# NUC505_v1 register map
File version: 1.0
Registers are 32-bit, read-write, reset 0x0 unless marked. A register's access mark holds for its fields unless they carry their own. Offsets are from the block's base; [hi:lo] are bit positions; lines under a group give offsets from that group; {n}, {i} and the like mark numbered series; 'fields as' and 'values as' point back to an identical list.

## GCR — GCR Register Map
Base 0x40000000
0x00 SYS_PDID ro reset 0x550505 — Part Device Identification Number Register
  [23:0] PDID — Part Device Identification Number (Read Only). This register reflects device part number code. Software can read this register to identify which device is used.
0x04 SYS_BOOTSET (reset mask 0xFFFFFF00) — System Power-on Configuration Register
  [3:0] BOOTSET — System Mode Configuration. Note: If BOOTSET is equal to ICE Mode, the software cannot change BOOTSET to other mode. But other modes don't have this limitation.
    6=Boot from ICE Mode with external SPI Flash; 7=Boot from ICE Mode with SPI Flash; 11=Boot from ICP Mode; 13=Boot from external SPI Flash; 14=Boot from USB; 15=Boot from SPI Flash
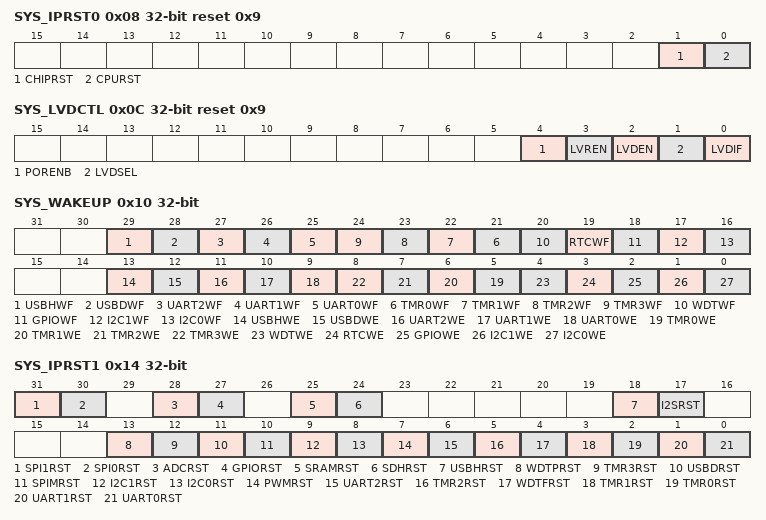
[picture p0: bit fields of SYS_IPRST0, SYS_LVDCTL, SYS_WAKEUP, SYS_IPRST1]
0x08 SYS_IPRST0 reset 0x9 — Peripheral Reset Control Register 0
  [1] CHIPRST — Chip One-shot Reset. Setting this bit will reset the whole chip, including processor core and all peripherals, and this bit will automatically return to 0 after the 2 clock cycles. The CHIPRST is same as the POR reset, all the chip controllers is reset and the chip setting from flash are also reload.
    0=Chip normal operation; 1=Chip one-shot reset
  [0] CPURST — Processor Core One-shot Reset. Setting this bit will only reset the processor core, and this bit will automatically return to 0 after the 2 clock cycles.
    0=Processor core normal operation; 1=Processor core one-shot reset
0x0C SYS_LVDCTL reset 0x9 — Low Voltage Detection Control Register
  [4] PORENB — Power on Reset Enable Control
    0=Function Enabled. (Default); 1=Function Disabled
  [3] LVREN — Low Voltage Reset Enable Control. Note: The voltage threshold level is 2.4V
    0=Low Voltage Reset Disabled; 1=Low Voltage Reset Enabled. (default)
  [2] LVDEN — Low Voltage Detection Enable Control
    0=Detection Disabled; 1=Detection Enabled
  [1] LVDSEL — Low Voltage Detection Level Selection
    0=The threshold level is 2.6V; 1=The threshold level is 2.8V
  [0] LVDIF — Low Voltage Detect Flag. Note: This bit is useful when LVDEN is enabled.
    0=Low voltage Period; 1=Normal voltage Period
0x10 SYS_WAKEUP — Wake-up Control and Status Resister
  [29] USBHWF — USB Host Wake-up Flag. Note: Write 1 to clear this bit
    0=USB Host wake-up source is deasserted; 1=USB Host wake-up source is asserted
  [28] USBDWF — USB Device Wake-up Flag. Note: Write 1 to clear this bit
    0=USB Device wake-up source is deasserted; 1=USB Device wake-up source is asserted
  [27] UART2WF — UART2 Wake-up Flag. Note: Write 1 to clear this bit
    0=UART2 wake-up source is deasserted; 1=UART2 wake-up source is asserted
  [26] UART1WF — UART1 Wake-up Flag. Note: Write 1 to clear this bit
    0=UART1 wake-up source is deasserted; 1=UART1 wake-up source is asserted
  [25] UART0WF — UART0 Wake-up Flag. Note: Write 1 to clear this bit
    0=UART0 wake-up source is deasserted; 1=UART0 wake-up source is asserted
  [n+21] TMR{n}WF (n=0..3) — Timer{n} Wake-up Flag. Note: Write 1 to clear this bit
    0=Timer{n} wake-up source is deasserted; 1=Timer{n} wake-up source is asserted
  [20] WDTWF — WDT Wake-up Flag. Note: Write 1 to clear this bit
    0=WDT wake-up source is deasserted; 1=WDT wake-up source is asserted
  [19] RTCWF — RTC Wake-up Flag. Note: Write 1 to clear this bit
    0=RTC wake-up source is deasserted; 1=RTC wake-up source is asserted
  [18] GPIOWF — GPIO Wake-up Flag. Note: Write 1 to clear this bit
    0=GPIO wake-up source is deasserted; 1=GPIO wake-up source is asserted
  [17] I2C1WF — I2C1 Wake-up Flag. Note: Write 1 to clear this bit
    0=I2C1 wake-up source is deasserted; 1=I2C1 wake-up source is asserted
  [16] I2C0WF — I2C0 Wake-up Flag. Note: Write 1 to clear this bit
    0=I2C0 wake-up source is deasserted; 1=I2C0 wake-up source is asserted
  [13] USBHWE — USB Host Wake-up Enable Control
    0=USB Host wake-up Disabled; 1=USB Host wake-up Enabled
  [12] USBDWE — USB Device Wake-up Enable Control
    0=USB Device wake-up Disabled; 1=USB Device wake-up Enabled
  [11] UART2WE — UART2 Wake-up Enable Control
    0=UART2 wake-up Disabled; 1=UART2 wake-up Enabled
  [10] UART1WE — UART1 Wake-up Enable Control
    0=UART1 wake-up Disabled; 1=UART1 wake-up Enabled
  [9] UART0WE — UART0 Wake-up Enable Control
    0=UART0 wake-up Disabled; 1=UART0 wake-up Enabled
  [n+5] TMR{n}WE (n=0..3) — Timer{n} Wake-up Enable Control
    0=Timer{n} wake-up Disabled; 1=Timer{n} wake-up Enabled
  [4] WDTWE — WDT Wake-up Enable Control
    0=WDT wake-up Disabled; 1=WDT wake-up Enabled
  [3] RTCWE — RTC Wake-up Enable Control
    0=RTC wake-up Disabled; 1=RTC wake-up Enabled
  [2] GPIOWE — GPIO Wake-up Enable Control
    0=GPIO wake-up Disabled; 1=GPIO wake-up Enabled
  [1] I2C1WE — I2C1 Wake-up Enable Control
    0=I2C1 wake-up Disabled; 1=I2C1 wake-up Enabled
  [0] I2C0WE — I2C0 Wake-up Enable Control
    0=I2C0 wake-up Disabled; 1=I2C0 wake-up Enabled
0x14 SYS_IPRST1 — Peripheral Reset Control Register 1
  [31] SPI1RST — SPI1 Controller Reset. Set this bit to 1 will generate a reset signal to the USB host controller. User needs to set this bit to 0 to release from the reset state.
    0=SPI1 controller normal operation; 1=SPI1 controller reset
  [30] SPI0RST — SPI0 Controller Reset. Set this bit to 1 will generate a reset signal to the USB host controller. User needs to set this bit to 0 to release from the reset state.
    0=SPI0 controller normal operation; 1=SPI0 controller reset
  [28] ADCRST — ADC Controller Reset. Set this bit to 1 will generate a reset signal to the USB host controller. User needs to set this bit to 0 to release from the reset state.
    0=ADC controller normal operation; 1=ADC controller reset
  [27] GPIORST — GPIO Controller Reset. Set this bit to 1 will generate a reset signal to the USB host controller. User needs to set this bit to 0 to release from the reset state.
    0=GPIO controller normal operation; 1=GPIO controller reset
  [25] SRAMRST — SRAM Controller Reset. Set this bit to 1 will generate a reset signal to the USB host controller. User needs to set this bit to 0 to release from the reset state.
    0=SRAM controller normal operation; 1=SRAM controller reset
  [24] SDHRST — SDH Controller Reset. Set this bit to 1 will generate a reset signal to the USB host controller. User needs to set this bit to 0 to release from the reset state.
    0=SDH controller normal operation; 1=SDH controller reset
  [18] USBHRST — USB Host Controller Reset. Setting this bit to 1 will generate a reset signal to the USB host controller. User needs to set this bit to 0 to release from the reset state.
    0=USB Host controller normal operation; 1=USB Host controller reset
  [17] I2SRST — I2S Controller Reset. Setting this bit to 1 will generate a reset signal to the USB host controller. User needs to set this bit to 0 to release from the reset state.
    0=I2S controller normal operation; 1=I2S controller reset
  [13] WDTPRST — WDT Controller Reset. Setting this bit to 1 will generate a reset signal to the USB host controller. User needs to set this bit to 0 to release from the reset state.
    0=WDT controller normal operation; 1=WDT controller reset
  [12] TMR3RST — Timer3 Controller Reset. Setting this bit to 1 will generate a reset signal to the USB host controller. User needs to set this bit to 0 to release from the reset state.
    0=Timer3 controller normal operation; 1=Timer3 controller reset
  [11] USBDRST — USB Device Controller Reset. Setting this bit to 1 will generate a reset signal to the USB host controller. User needs to set this bit to 0 to release from the reset state.
    0=USB Device controller normal operation; 1=USB Device controller reset
  [10] SPIMRST — SPIM Controller Reset. Setting this bit to 1 will generate a reset signal to the USB host controller. User needs to set this bit to 0 to release from the reset state.
    0=SPIM controller normal operation; 1=SPIM controller reset
  [9] I2C1RST — I2C1 Controller Reset. Setting this bit to 1 will generate a reset signal to the USB host controller. User needs to set this bit to 0 to release from the reset state.
    0=I2C1 controller normal operation; 1=I2C1 controller reset
  [8] I2C0RST — I2C0 Controller Reset. Setting this bit to 1 will generate a reset signal to the USB host controller. User needs to set this bit to 0 to release from the reset state.
    0=I2C0 controller normal operation; 1=I2C0 controller reset
  [7] PWMRST — PWM Controller Reset. Setting this bit to 1 will generate a reset signal to the USB host controller. User needs to set this bit to 0 to release from the reset state.
    0=PWM controller normal operation; 1=PWM controller reset
  [6] UART2RST — UART2 Controller Reset. Setting this bit to 1 will generate a reset signal to the USB host controller. User needs to set this bit to 0 to release from the reset state.
    0=UART2 controller normal operation; 1=UART2 controller reset
  [5] TMR2RST — Timer2 Controller Reset. Setting this bit to 1 will generate a reset signal to the USB host controller. User needs to set this bit to 0 to release from the reset state.
    0=Timer2 controller normal operation; 1=Timer2 controller reset
  [4] WDTFRST — WDT Hardware Controller Reset. Setting this bit to 1 will generate a reset signal to the USB host controller. User needs to set this bit to 0 to release from the reset state.
    0=WDT controller normal operation; 1=WDT controller reset
  [3] TMR1RST — Timer1 Controller Reset. Setting this bit to 1 will generate a reset signal to the USB host controller. User needs to set this bit to 0 to release from the reset state.
    0=Timer1 controller normal operation; 1=Timer1 controller reset
  [2] TMR0RST — Timer0 Controller Reset. Setting this bit to 1 will generate a reset signal to the USB host controller. User needs to set this bit to 0 to release from the reset state.
    0=Timer0 controller normal operation; 1=Timer0 controller reset
  [1] UART1RST — UART1 Controller Reset. Setting this bit to 1 will generate a reset signal to the USB host controller. User needs to set this bit to 0 to release from the reset state.
    0=UART1 controller normal operation; 1=UART1 controller reset
  [0] UART0RST — UART0 Controller Reset. Setting this bit to 1 will generate a reset signal to the USB host controller. User needs to set this bit to 0 to release from the reset state.
    0=UART0 controller normal operation; 1=UART0 controller reset
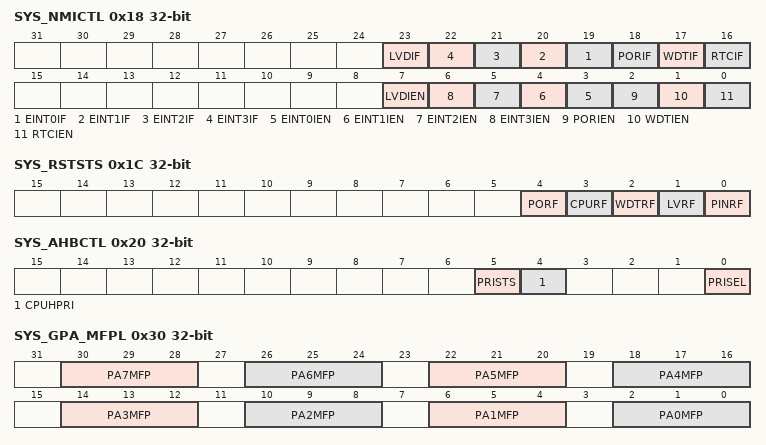
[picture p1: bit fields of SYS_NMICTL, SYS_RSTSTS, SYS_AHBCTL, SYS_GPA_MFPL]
0x18 SYS_NMICTL — Non Maskable Interrupt Control Register
  [23] LVDIF ro — Low Voltage Detect (LVD) Interrupt Flag (Read Only)
    0=LVD interrupt is deasserted; 1=LVD interrupt is asserted
  [n+19] EINT{n}IF ro (n=0..3) — External GPIO Group {n} Interrupt Flag (Read Only)
    0=External GPIO group {n} interrupt is deasserted; 1=External GPIO group {n} interrupt is asserted
  [18] PORIF ro — Power on Reset (POR) Interrupt Flag (Read Only)
    0=POR interrupt is deasserted; 1=POR interrupt is asserted
  [17] WDTIF ro — Watch Dog Timer (WDT) Interrupt Flag (Read Only)
    0=WDT interrupt is deasserted; 1=WDT interrupt is asserted
  [16] RTCIF ro — RTC Interrupt Flag (Read Only)
    0=RTC interrupt is deasserted; 1=RTC interrupt is asserted
  [7] LVDIEN — Low Voltage Detect NMI Source Enable Control
    0=LVD NMI source Disabled; 1=LVD NMI source Enabled
  [n+3] EINT{n}IEN (n=0..3) — External GPIO Group {n} NMI Source Enable Control
    0=External GPIO group {n} NMI source Disabled; 1=External GPIO group {n} NMI source Enabled
  [2] PORIEN — Power on Interrupt NMI Source Enable Control
    0=POR NMI source Disabled; 1=POR NMI source Enabled
  [1] WDTIEN — WDT Interrupt NMI Source Enable Control
    0=WDT NMI source Disabled; 1=WDT NMI source Enabled
  [0] RTCIEN — RTC Interrupt NMI Source Enable Control
    0=RTC NMI source Disabled; 1=RTC NMI source Enabled
0x1C SYS_RSTSTS — Reset Status Control Register
  [4] PORF — Reset Status for POR Reset. Note: Write 1 to clear this bit to 0.
    0=No effect; 1=Power-on Reset (POR) had issued the reset signal to reset the system
  [3] CPURF — Reset Status for Software Setting. Note: Write 1 to clear this bit to 0.
    0=No effect; 1=The CPURST had be triggered to reset the CPU or the CHIPREST had be triggered to reset the system
  [2] WDTRF — Reset Status for Watch Dog Reset. Note: Write 1 to clear this bit to 0.
    0=No effect; 1=The watchdog timer or window watchdog timer had issued the reset signal to reset the system
  [1] LVRF — Reset Status for Low Voltage Reset. Note: Write 1 to clear this bit to 0.
    0=No effect; 1=LVR controller had issued the reset signal to reset the system
  [0] PINRF — Reset Status for External NReset Pin. Note: Write 1 to clear this bit to 0.
    0=No effect; 1=nRESET pin had issued the reset signal to reset the system
0x20 SYS_AHBCTL — AHB Bus Control Register
  [5] PRISTS — Interrupt Active Status in CPUHPRI Enabled Mode. If it is high, the CPU has the highest AHB bus priority. It is set when the CPUHPRI is enabled and the external IRQ is active. This bit is cleared by writing 1 to it. Therefore, if exiting from the IRQ when CPUHPRI is enabled, PRISTS must be cleared. Otherwise, the CPU always has the highest AHB bus priority.
    0=No effect; 1=The highest AHB bus priority for CPU is active
  [4] CPUHPRI — Enable Raising the Priority of CPU in IRQ Period. It can be used to reduce the interrupt latency in a real-time system. Setting this bit, the CPU will have the highest AHB priority.
    0=No effect; 1=The function that CPU has the highest AHB bus priority in IRQ period Enabled
  [0] PRISEL — AHB Bus Arbitration Mode Control. The priority mode for fixed priority mode is I2S SDH USBH USBD SPIM M4(S) M4(D) M4(I)
    0=Fixed priority mode; 1=Round-robin priority mode (rotate)
0x30 SYS_GPA_MFPL — GPIOA Low Byte Multi-function Control Register
  [30:28] PA7MFP — PA.7 Multi-function Pin Selection
  [26:24] PA6MFP — PA.6 Multi-function Pin Selection
  [22:20] PA5MFP — PA.5 Multi-function Pin Selection
  [18:16] PA4MFP — PA.4 Multi-function Pin Selection
  [14:12] PA3MFP — PA.3 Multi-function Pin Selection
  [10:8] PA2MFP — PA.2 Multi-function Pin Selection
  [6:4] PA1MFP — PA.1 Multi-function Pin Selection
  [2:0] PA0MFP — PA.0 Multi-function Pin Selection
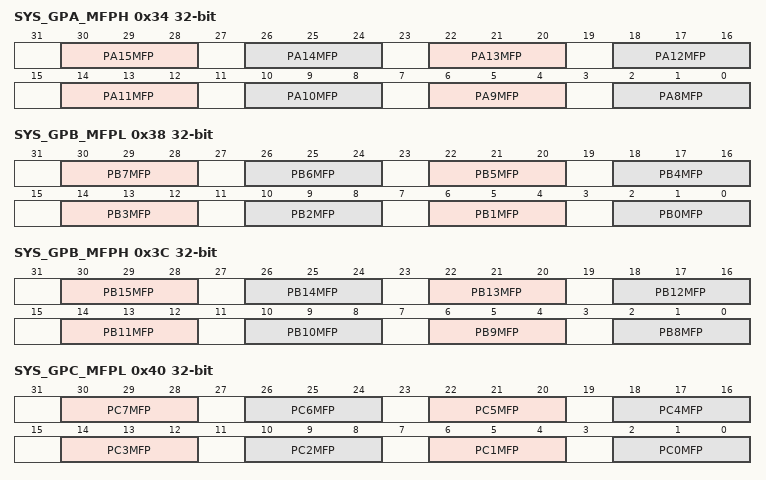
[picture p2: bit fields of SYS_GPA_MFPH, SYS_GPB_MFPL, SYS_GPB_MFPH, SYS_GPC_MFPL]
0x34 SYS_GPA_MFPH — GPIOA High Byte Multi-function Control Register
  [30:28] PA15MFP — PA.15 Multi-function Pin Selection
  [26:24] PA14MFP — PA.14 Multi-function Pin Selection
  [22:20] PA13MFP — PA.13 Multi-function Pin Selection
  [18:16] PA12MFP — PA.12 Multi-function Pin Selection
  [14:12] PA11MFP — PA.11 Multi-function Pin Selection
  [10:8] PA10MFP — PA.10 Multi-function Pin Selection
  [6:4] PA9MFP — PA.9 Multi-function Pin Selection
  [2:0] PA8MFP — PA.8 Multi-function Pin Selection
0x38 SYS_GPB_MFPL — GPIOB Low Byte Multi-function Control Register
  [30:28] PB7MFP — PB.7 Multi-function Pin Selection
  [26:24] PB6MFP — PB.6 Multi-function Pin Selection
  [22:20] PB5MFP — PB.5 Multi-function Pin Selection
  [18:16] PB4MFP — PB.4 Multi-function Pin Selection
  [14:12] PB3MFP — PB.3 Multi-function Pin Selection
  [10:8] PB2MFP — PB.2 Multi-function Pin Selection
  [6:4] PB1MFP — PB.1 Multi-function Pin Selection
  [2:0] PB0MFP — PB.0 Multi-function Pin Selection
0x3C SYS_GPB_MFPH — GPIOB High Byte Multi-function Control Register
  [30:28] PB15MFP — PB.15 Multi-function Pin Selection
  [26:24] PB14MFP — PB.14 Multi-function Pin Selection
  [22:20] PB13MFP — PB.13 Multi-function Pin Selection
  [18:16] PB12MFP — PB.12 Multi-function Pin Selection
  [14:12] PB11MFP — PB.11 Multi-function Pin Selection
  [10:8] PB10MFP — PB.10 Multi-function Pin Selection
  [6:4] PB9MFP — PB.9 Multi-function Pin Selection
  [2:0] PB8MFP — PB.8 Multi-function Pin Selection
0x40 SYS_GPC_MFPL — GPIOC Low Byte Multi-function Control Register
  [30:28] PC7MFP — PC.7 Multi-function Pin Selection
  [26:24] PC6MFP — PC.6 Multi-function Pin Selection
  [22:20] PC5MFP — PC.5 Multi-function Pin Selection
  [18:16] PC4MFP — PC.4 Multi-function Pin Selection
  [14:12] PC3MFP — PC.3 Multi-function Pin Selection
  [10:8] PC2MFP — PC.2 Multi-function Pin Selection
  [6:4] PC1MFP — PC.1 Multi-function Pin Selection
  [2:0] PC0MFP — PC.0 Multi-function Pin Selection
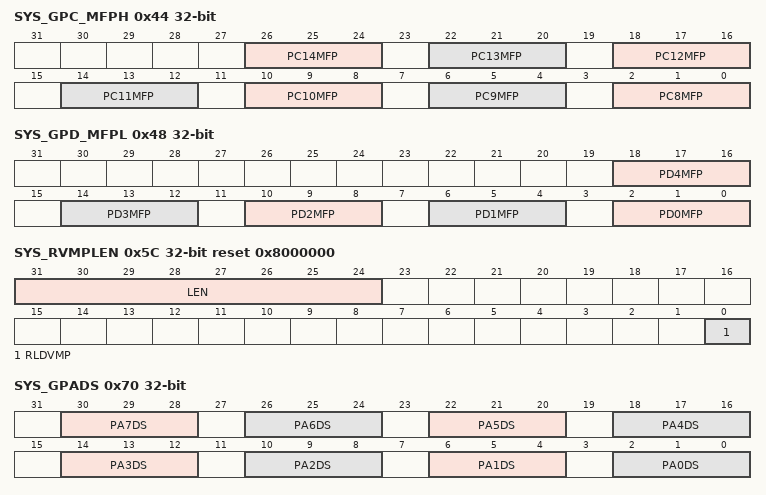
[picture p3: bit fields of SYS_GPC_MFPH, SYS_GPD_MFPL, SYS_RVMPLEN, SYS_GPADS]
0x44 SYS_GPC_MFPH — GPIOC High Byte Multi-function Control Register
  [26:24] PC14MFP — PC.14 Multi-function Pin Selection
  [22:20] PC13MFP — PC.13 Multi-function Pin Selection
  [18:16] PC12MFP — PC.12 Multi-function Pin Selection
  [14:12] PC11MFP — PC.11 Multi-function Pin Selection
  [10:8] PC10MFP — PC.10 Multi-function Pin Selection
  [6:4] PC9MFP — PC.9 Multi-function Pin Selection
  [2:0] PC8MFP — PC.8 Multi-function Pin Selection
0x48 SYS_GPD_MFPL — GPIOD Low Byte Multi-function Control Register
  [18:16] PD4MFP — PD.4 Multi-function Pin Selection
  [14:12] PD3MFP — PD.3 Multi-function Pin Selection
  [10:8] PD2MFP — PD.2 Multi-function Pin Selection
  [6:4] PD1MFP — PD.1 Multi-function Pin Selection
  [2:0] PD0MFP — PD.0 Multi-function Pin Selection
0x50 SYS_LVMPADDR reset 0x1FFF0000 — Load VECMAP Address Parameter Control Register
  [31:0] ADDR — Load VECMAP Address Register. This is the start address for mapping to the address 0x0000_0000 in VECMAP function. Only when CPU reset or setting RLDVMP to 1, the loading signal will be loaded to the SYS_RVMPADDR register. Note: This register can only be reset by CHIPRST and HW Reset.
0x54 SYS_LVMPLEN reset 0x8 — Load VECMAP Length Parameter Control Register
  [7:0] LEN — LD_VECMAP Length. This is the memory length loading signal for mapping to the address 0x0000_0000 in VECMAP function. Only when OCPU reset or setting RLDVMP to 1, the loading signal will be loaded to the SYS_RVMPLEN register. Note1: The maximum mapping length is 128K bytes. Note2: This register only can be reset by CHIPRST and HW Reset.
0x58 SYS_RVMPADDR ro reset 0x1FFF0000 — Real VECMAP Address Parameter Register
  [31:0] ADDR — Real VECMAP Address Register Parameter. This is the real start address parameter for mapping to the address 0x0000_0000 in VECMAP function. (Default value is mapping to IBR_ROM start address.). Note: This register is only loaded from ADDR during CPU Reset process (SYS_IPRST0[0]) or setting RLDVMP.
0x5C SYS_RVMPLEN reset 0x8000000 — Real VECMAP Length Parameter Control Register
  [31:24] LEN — Real VECMAP Length. This is the real memory length for mapping to the address 0x0000_0000 in VECMAP function. Note1: Read Only. Note2: These bits are only loaded from LEN when setting CPURST (SYS_IPRST0[0]) or setting RLDVMP.
  [0] RLDVMP — Load VECMAP Parameter Signal. Note: This bit is auto cleared to 0
    0=No effect; 1=Load VECMAP Address and Length
0x6C SYS_EPADPUEN reset 0x1F — Embedded SPI Flash Pad Pull-up Enable Control Register
  [4:0] EPADPUEN — Embedded SPI Flash Pad Pull-up Enable Control. Note: In Power-down mode, user should set EPADPUEN[4:0] to 0x12.
    0=All embedded pads are pull-up Disabled; 18=Only SPI Flash MISO pads are pull-up Enabled; 31=All embedded pads are pull-up Enabled
0x70 SYS_GPADS — GPIOA Driving Strength Control Register
  [all] fields
    0=2.0 mA (Default); 1=6.5 mA; 2=8.7 mA; 3=13.0 mA; 4=15.2 mA; 5=19.5 mA; 6=21.7 mA; 7=26.1 mA
  [30:28] PA7DS — PA.7 Driving Strength Control. Setting driving strength for PA.7 analog / digital combo pin.
  [26:24] PA6DS — PA.6 Driving Strength Control. Setting driving strength for PA.6 analog / digital combo pin.
  [22:20] PA5DS — PA.5 Driving Strength Control. Setting driving strength for PA.5 analog / digital combo pin.
  [18:16] PA4DS — PA.4 Driving Strength Control. Setting driving strength for PA.4 analog / digital combo pin.
  [14:12] PA3DS — PA.3 Driving Strength Control. Setting driving strength for PA.3 analog / digital combo pin.
  [10:8] PA2DS — PA.2 Driving Strength Control. Setting driving strength for PA.2 analog / digital combo pin.
  [6:4] PA1DS — PA.1 Driving Strength Control. Setting driving strength for PA.1 analog / digital combo pin.
  [2:0] PA0DS — PA.0 Driving Strength Control. Setting driving strength for PA.0 analog / digital combo pin.
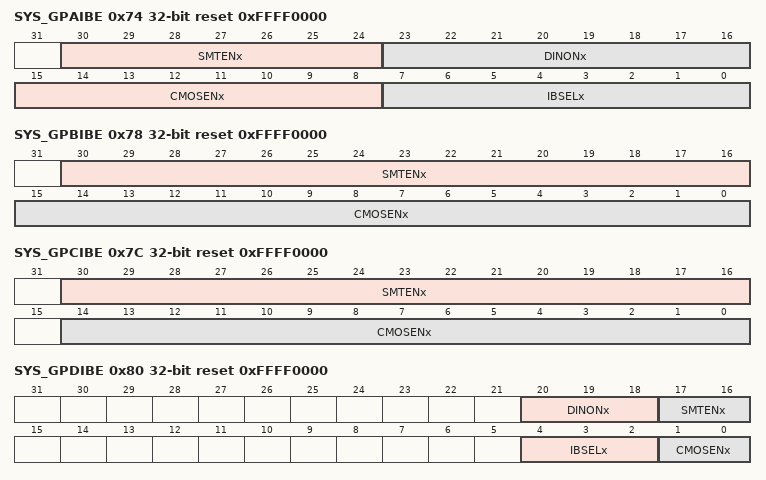
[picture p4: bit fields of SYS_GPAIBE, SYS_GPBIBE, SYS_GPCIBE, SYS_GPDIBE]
0x74 SYS_GPAIBE reset 0xFFFF0000 — GPIOA Input Buffer Enable Control Register
  [30:24] SMTENx — Note: If both Schmitt Trigger and CMOS input buffer are set to 0, the input signal from PAD will always be zero.
    0=PA.x schmitt Trigger Input Buffer Disabled; 1=PA.x schmitt Trigger Input Buffer Enabled (Default)
  [23:16] DINONx — Note1: If setting to 0, the input signal from PAD will always be zero. Note2: If using PA.0~PA.7 as analog pads, remember to disable input buffer.
    0=PA.x Input Buffer Disabled; 1=PA.x Input Buffer Enabled (Default)
  [15:8] CMOSENx — Note: If both Schmitt Trigger and CMOS input buffer are set to 0, the input signal from PAD will always be zero.
    0=PA.x CMOS Input Buffer Disabled. (Default); 1=PA.x CMOS Input Buffer Enabled
  [7:0] IBSELx
    0=PA.x CMOS Input Buffer (Default); 1=PA.x Schmitt Trigger Input Buffer
0x78 SYS_GPBIBE reset 0xFFFF0000 — GPIOB Input Buffer Enable Control Register
  [30:16] SMTENx — Note: If both Schmitt Trigger and CMOS input buffer are set to 0, the input signal from PAD will always be zero.
    0=PB.x Schmitt Trigger Input Buffer Disabled; 1=PB.x Schmitt Trigger Input Buffer Enabled (Default)
  [15:0] CMOSENx — Note: If both Schmitt Trigger and CMOS input buffer are set to 0, the input signal from PAD will always be zero.
    0=PB.x CMOS Input Buffer Disabled. (Default); 1=PB.x CMOS Input Buffer Enabled
0x7C SYS_GPCIBE reset 0xFFFF0000 — GPIOC Input Buffer Enable Control Register
  [30:16] SMTENx — Note: If both Schmitt Trigger and CMOS input buffer are set to 0, the input signal from PAD will always be zero.
    0=PC.x Schmitt Trigger Input Buffer Disabled; 1=PC.x Schmitt Trigger Input Buffer Enabled (Default)
  [14:0] CMOSENx — Note: If both Schmitt Trigger and CMOS input buffer are set to 0, the input signal from PAD will always be zero.
    0=PC.x CMOS Input Buffer Disabled. (Default); 1=PC.x CMOS Input Buffer Enabled
0x80 SYS_GPDIBE reset 0xFFFF0000 — GPIOD Input Buffer Enable Control Register
  [20:18] DINONx — Note1: If setting to 0, the input signal from PAD will always be zero. Note2: If using PD.2, PD.3, and PD.4 as analog pads, user must disable PD.2, PD.3, and PD.4 input buffer.
    0=PD.x Input Buffer Disabled; 1=PD.x Input Buffer Enabled (Default)
  [17:16] SMTENx — Note: If both Schmitt Trigger and CMOS input buffer are set to 0, the input signal from PAD will always be zero.
    0=PD.x Schmitt Trigger Input Buffer Disabled; 1=PD.x Schmitt Trigger Input Buffer Enabled (Default)
  [4:2] IBSELx
    0=PD.x CMOS Input Buffer (Default); 1=PD.x Schmitt Trigger Input Buffer
  [1:0] CMOSENx — Note: If both Schmitt Trigger and CMOS input buffer are set to 0, the input signal from PAD will always be zero.
    0=PD.x CMOS Input Buffer Disabled (Default); 1=PD.x CMOS Input Buffer Enabled
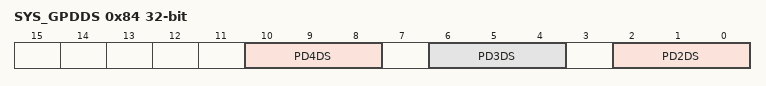
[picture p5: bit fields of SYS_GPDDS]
0x84 SYS_GPDDS — GPIOD Driving Strength Control Register
  [all] fields
    values as the fields of SYS_GPADS
  [10:8] PD4DS — PD.4 Driving Strength Control. Setting driving strength for PD.4 analog / digital combo pin.
  [6:4] PD3DS — PD.3 Driving Strength Control. Setting driving strength for PD.3 analog / digital combo pin.
  [2:0] PD2DS — PD.2 Driving Strength Control. Setting driving strength for PD.2 analog / digital combo pin.
0x100 SYS_RSTDBCNT reset 0x4B0 — External NRESET Pin De-bounce Counter Control Register
  [15:0] RSTDBCNT — External NRESET De-bounce Counter
0x104 SYS_RSTDBEN — External NRESET Pin De-bounce Control Register
  [0] RSTDBEN — External NRESET De-bounce Control. This bit is to enable or disable the external nRESET pin de-bounce process.
    0=De-bounce function Disabled; 1=De-bounce function Enabled
